# pass register map
Vendor: Texas Instruments
Peripheral module from a debugger description file (folder Keystone).
Registers are 32-bit, read-only, no defined reset value unless marked. A register's access mark holds for its fields unless they carry their own. Offsets are as the file gives them; lines under a group give offsets from that group; [hi:lo] are bit positions; {n}, {i} and the like mark numbered series; 'fields as' and 'values as' point back to an identical list; <NAME> marks a mode.

## NETCP
0x00 MBOX_SLOT rw — (1 of 6, stride 16)
  [31:0] status_bits
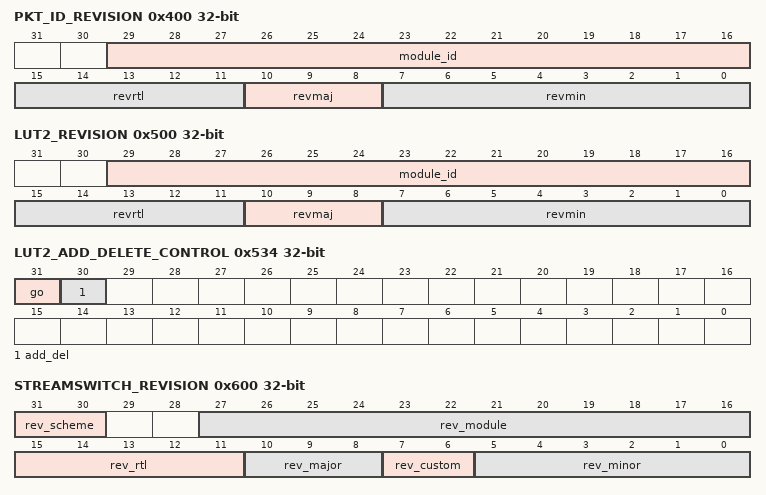
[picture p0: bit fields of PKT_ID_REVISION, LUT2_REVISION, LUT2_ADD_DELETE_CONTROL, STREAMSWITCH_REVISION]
0x400 PKT_ID_REVISION — (1 of 1, stride 0)
  [29:16] module_id
  [15:11] revrtl — RTL revision
  [10:8] revmaj — Major revision
  [7:0] revmin — Minor revision
0x404 PKT_ID_SOFT_RESET wo — (1 of 1, stride 0)
  [31:0] trigger — Writing anything to this field causes all internal statistics to be cleared
0x408 PKT_ID_RANGE_LIMIT rw — (1 of 1, stride 0)
  [9:0] range_limit — Contains the value of the highest allowable ID returned by allocation
0x40C PKT_ID_VALUE rw — (1 of 1, stride 0)
  [10:0] id_value — When read, returns the value of a newly allocated packet ID, or returns 0x400 when no packet ID is available. When written, frees the supplied packet ID.
0x500 LUT2_REVISION — (1 of 1, stride 0)
  fields as PKT_ID_REVISION
0x504 LUT2_SOFT_RESET wo — (1 of 1, stride 0)
  [31:0] trigger — Writing anything to this field causes the LUT to be cleared. This operation takes 2 clock cycles to complete.
0x520 LUT2_ADD_DATA_N rw — (1 of 1, stride 0)
  [31:0] data — This is the data which will be placed in bits ((32*N)+31):(32*N) of the data portion of the added table entry.
0x530 LUT2_ADD_DELETE_KEY rw — (1 of 1, stride 0)
  [31:0] key — This is the key which will be matched against during the search operation.
0x534 LUT2_ADD_DELETE_CONTROL rw — (1 of 1, stride 0)
  [31] go — Go bit. Writing this bit will cause the add / delete operation to start. Once started, the operation cannot be cancelled. This bit will remain asserted until the add or delete operation completes.
  [30] add_del — Add / delete control bit: 0=Delete entry, 1=Add entry
0x600 STREAMSWITCH_REVISION — (1 of 1, stride 0)
  [31:30] rev_scheme — Scheme
  [27:16] rev_module — Module ID
  [15:11] rev_rtl — RTL revisions
  [10:8] rev_major — Major revision
  [7:6] rev_custom — Custom revision
  [5:0] rev_minor — Minor revision
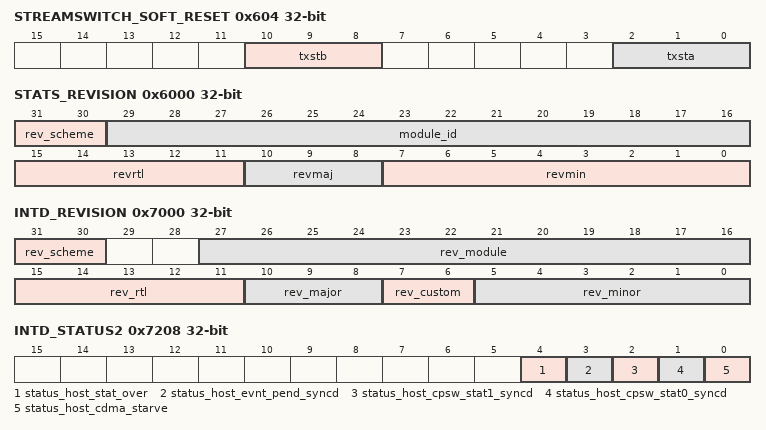
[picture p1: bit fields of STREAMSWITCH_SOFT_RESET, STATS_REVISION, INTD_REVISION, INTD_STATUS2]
0x604 STREAMSWITCH_SOFT_RESET rw — (1 of 1, stride 0)
  [10:8] txstb — This field maps the CPSW txstb port to a physical slave thread.
  [2:0] txsta — This field maps the CPSW txsta port to a physical slave thread.
0x6000 STATS_REVISION — (1 of 1, stride 0)
  [31:30] rev_scheme — Scheme
  [29:16] module_id
  [15:11] revrtl — RTL revision
  [10:8] revmaj — Major revision
  [7:0] revmin — Minor revision
0x6004 STATS_SOFT_RESET wo — (1 of 1, stride 0)
  [31:0] trigger — Writing anything to this field causes all internal statistics to be cleared.
0x6008 STATS_INC_FLAGS wo — (1 of 1, stride 0)
  [31:0] inc_flags — Each flag corresponds to a statistic to increment. Bit 0 corresponds to the Statistic 0 register. The amount to increment is 1.
0x600C STATS_CAPTURE wo — (1 of 1, stride 0)
  [31:0] stat_capture — Each flag corresponds to a statistic. Bit 0 corresponds to the Statistic 0 register. Writing any value to this register causes all 32 statistic values to be captured. For any bit that is set to 1, the corresponding statistic is also cleared after being
0x6020 STATS_COUNT_N — (1 of 1, stride 0)
  [31:0] stat_count — Holds the 32-bit value of the statistic.
0x7000 INTD_REVISION — (1 of 1, stride 0)
  fields as STREAMSWITCH_REVISION
0x7010 INTD_EOI rw — (1 of 1, stride 0)
  [7:0] eoi_vector — End of Interrupt Vector
0x7014 INTD_INTR_VECTOR — (1 of 1, stride 0)
  [31:0] intr_vector — Interrupt Vector Register
0x7200 INTD_STATUS0 rw — (1 of 1, stride 0)
  [31:0] status_host_in_intr — Status (write 1 to set) for in_intr
0x7204 INTD_STATUS1 — (1 of 1, stride 0)
  [31:0] status_host_lintr — Status for lintr
0x7208 INTD_STATUS2 access per field — (1 of 1, stride 0)
  [4] status_host_stat_over ro — Status for stat_over
  [3] status_host_evnt_pend_syncd ro — Status for evnt_pend
  [2] status_host_cpsw_stat1_syncd ro — Status for cpsw_stat1
  [1] status_host_cpsw_stat0_syncd ro — Status for cpsw_stat0
  [0] status_host_cdma_starve rw — Status (write 1 to set) for cdma_starve
0x7280 INTD_STATUS_CLR0 wo — (1 of 1, stride 0)
  [31:0] status_host_in_intr_clr — Status (write 1 to clear) for in_intr
0x7288 INTD_STATUS_CLR2 wo — (1 of 1, stride 0)
  [0] status_host_cdma_starve_clr — Status (write 1 to clear) for cdma_starve
0x7300 INTD_INTCNT — (1 of 1, stride 0)
  [7:0] intcnt_host_cnt_in_intr — Interrupt Count for host_cnt_in_intr (write to decrement)
0x7480 INTD_INTR_VECTOR_HOST — (1 of 1, stride 0)
  [31:0] intr_vector_host — Interrupt Vector
